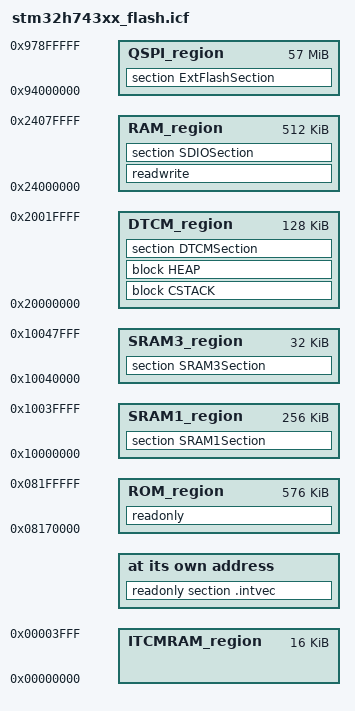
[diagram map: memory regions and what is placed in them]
/*###ICF### Section handled by ICF editor, don't touch! ****/
/*-Editor annotation file-*/
/* IcfEditorFile="$TOOLKIT_DIR$\config\ide\IcfEditor\cortex_v1_0.xml" */
/*-Specials-*/
define symbol __ICFEDIT_intvec_start__ = __C_START_ADDR;
/*-Memory Regions-*/
define symbol __ICFEDIT_region_ROM_start__     = 0x08170000;
define symbol __ICFEDIT_region_ROM_end__       = 0x081FFFFF;
define symbol __ICFEDIT_region_RAM_start__     = 0x24000000;
define symbol __ICFEDIT_region_RAM_end__       = 0x2407FFFF;
define symbol __ICFEDIT_region_ITCMRAM_start__ = 0x00000000;
define symbol __ICFEDIT_region_ITCMRAM_end__   = 0x00003FFF;
/*-Sizes-*/
define symbol __ICFEDIT_size_cstack__ = 0x1000;
define symbol __ICFEDIT_size_heap__   = 0x800;
/**** End of ICF editor section. ###ICF###*/

define symbol __region_QSPI_start__ = 0x94000000;
define symbol __region_QSPI_end__   = 0x978FFFFF;

define symbol __region_DTCM_start__ = 0x20000000;
define symbol __region_DTCM_end__   = 0x2001FFFF;

define symbol __region_SRAM1_start__ = 0x10000000;
define symbol __region_SRAM1_end__   = 0x1003FFFF;

define symbol __region_SRAM3_start__ = 0x10040000;
define symbol __region_SRAM3_end__   = 0x10047FFF;

define memory mem with size = 4G;
define region ROM_region   = mem:[from __ICFEDIT_region_ROM_start__   to __ICFEDIT_region_ROM_end__];
define region RAM_region   = mem:[from __ICFEDIT_region_RAM_start__   to __ICFEDIT_region_RAM_end__];
define region DTCM_region   = mem:[from __region_DTCM_start__   to __region_DTCM_end__];
define region SRAM1_region   = mem:[from __region_SRAM1_start__   to __region_SRAM1_end__];
define region SRAM3_region   = mem:[from __region_SRAM3_start__   to __region_SRAM3_end__];
define region QSPI_region   = mem:[from __region_QSPI_start__ to __region_QSPI_end__];
define region ITCMRAM_region  = mem:[from __ICFEDIT_region_ITCMRAM_start__ to __ICFEDIT_region_ITCMRAM_end__];

define block CSTACK    with alignment = 8, size = __ICFEDIT_size_cstack__   { };
define block HEAP      with alignment = 8, size = __ICFEDIT_size_heap__     { };

initialize by copy { readwrite };
do not initialize  { section .noinit };

place at address mem:__ICFEDIT_intvec_start__ { readonly section .intvec };

place in ROM_region   { readonly };
place in RAM_region   { readwrite, section SDIOSection };

place in QSPI_region { section ExtFlashSection };

place in DTCM_region { block CSTACK, block HEAP, section DTCMSection };

place in SRAM1_region { section SRAM1Section };
place in SRAM3_region { section SRAM3Section };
